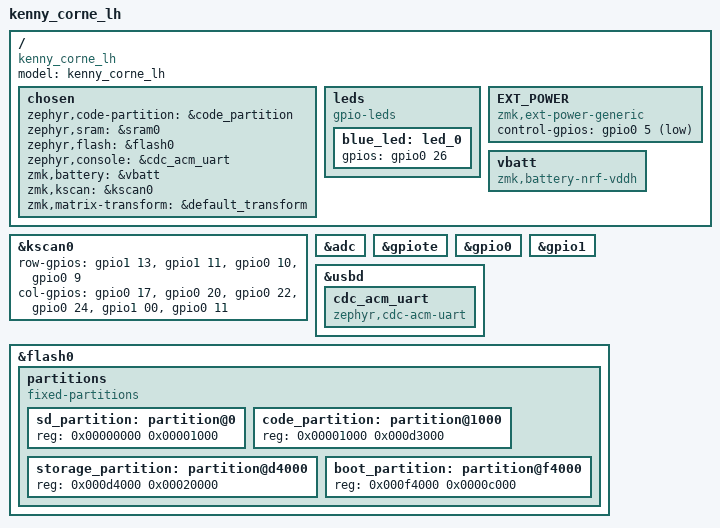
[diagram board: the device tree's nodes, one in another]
/dts-v1/;
#include <nordic/nrf52840_qiaa.dtsi>

#include <dt-bindings/led/led.h>
#include <dt-bindings/zmk/matrix_transform.h>

#include "kenny_corne.dtsi"
#include "kenny_corne_lh-pinctrl.dtsi"

/ {
    model = "kenny_corne_lh";
    compatible = "kenny_corne_lh";

    chosen {
        zephyr,code-partition = &code_partition;
        zephyr,sram = &sram0;
        zephyr,flash = &flash0;
        zephyr,console = &cdc_acm_uart;
        zmk,battery = &vbatt;
        zmk,kscan = &kscan0;
        zmk,matrix-transform = &default_transform;
    };

    leds {
        compatible = "gpio-leds";
        blue_led: led_0 {
            gpios = <&gpio0 26 GPIO_ACTIVE_HIGH>;
        };
    };

    // Node name must match original "EXT_POWER" label to preserve user settings.
    EXT_POWER {
        compatible = "zmk,ext-power-generic";
        control-gpios = <&gpio0 5 GPIO_ACTIVE_LOW>;
    };

    vbatt: vbatt {
        compatible = "zmk,battery-nrf-vddh";
    };
};

&kscan0 {
    row-gpios
        = <&gpio1 13 (GPIO_ACTIVE_HIGH | GPIO_PULL_DOWN)>
        , <&gpio1 11 (GPIO_ACTIVE_HIGH | GPIO_PULL_DOWN)>
        , <&gpio0 10 (GPIO_ACTIVE_HIGH | GPIO_PULL_DOWN)>
        , <&gpio0  9 (GPIO_ACTIVE_HIGH | GPIO_PULL_DOWN)>
        ;
    col-gpios
        = <&gpio0 17 GPIO_ACTIVE_HIGH>
        , <&gpio0 20 GPIO_ACTIVE_HIGH>
        , <&gpio0 22 GPIO_ACTIVE_HIGH>
        , <&gpio0 24 GPIO_ACTIVE_HIGH>
        , <&gpio1 00 GPIO_ACTIVE_HIGH>
        , <&gpio0 11 GPIO_ACTIVE_HIGH>
        ;
};

&adc {
    status = "okay";
};

&gpiote {
    status = "okay";
};

&gpio0 {
    status = "okay";
};

&gpio1 {
    status = "okay";
};

&usbd {
    status = "okay";
    cdc_acm_uart: cdc_acm_uart {
        compatible = "zephyr,cdc-acm-uart";
    };
};

&flash0 {
    /*
     * For more information, see:
     * http://docs.zephyrproject.org/latest/devices/dts/flash_partitions.html
     */
    partitions {
        compatible = "fixed-partitions";
        #address-cells = <1>;
        #size-cells = <1>;

        sd_partition: partition@0 {
            reg = <0x00000000 0x00001000>;
        };

        code_partition: partition@1000 {
            reg = <0x00001000 0x000d3000>;
        };

        /*
         * The flash starting at 0x000d4000 and ending at
         * 0x000f3fff is reserved for use by the application.
         */

        /*
         * Storage partition will be used by FCB/LittleFS/NVS
         * if enabled.
         */
        storage_partition: partition@d4000 {
            reg = <0x000d4000 0x00020000>;
        };

        boot_partition: partition@f4000 {
            reg = <0x000f4000 0x0000c000>;
        };
    };
};
